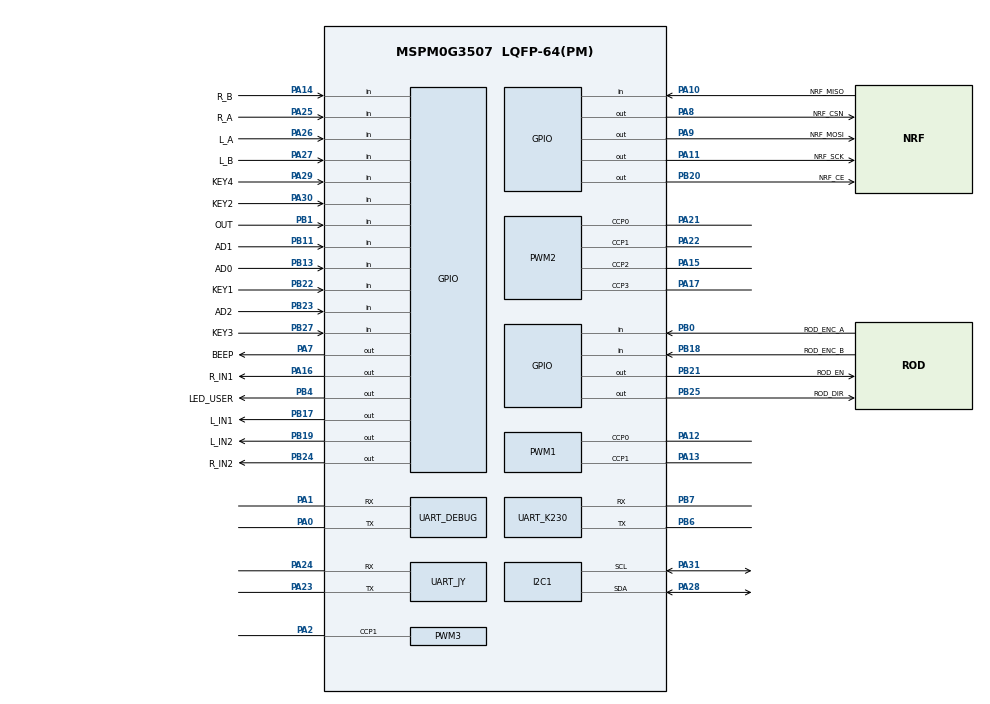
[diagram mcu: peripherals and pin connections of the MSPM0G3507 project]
/**
 * Revised local SysConfig script for the MSPM0G3507 E-car board.
 *
 * This file mirrors the checked-in ti_msp_dl_config.c/h logical names.
 * If SysConfig regenerates different macro names, keep App/Hardware code
 * mapped through Hardware/Board_Config.h.
 */
//@cliArgs --device "MSPM0G350X" --package "LQFP-64(PM)" --part "Default"
//@v2CliArgs --device "MSPM0G3507" --package "LQFP-64(PM)"
// @cliArgs --board /ti/boards/LP_MSPM0G3507 --rtos nortos

const GPIO   = scripting.addModule("/ti/driverlib/GPIO", {}, false);
const GPIO1  = GPIO.addInstance();
const GPIO2  = GPIO.addInstance();
const GPIO3  = GPIO.addInstance();
const GPIO4  = GPIO.addInstance();
const GPIO5  = GPIO.addInstance();
const GPIO_NRF = GPIO.addInstance();
const GPIO_RodStepper = GPIO.addInstance();
const GPIO_RodEncoder = GPIO.addInstance();
const I2C    = scripting.addModule("/ti/driverlib/I2C", {}, false);
const I2C1   = I2C.addInstance();
const PWM    = scripting.addModule("/ti/driverlib/PWM", {}, false);
const PWM1   = PWM.addInstance();
const PWM2   = PWM.addInstance();
const PWM3   = PWM.addInstance();
const TIMER  = scripting.addModule("/ti/driverlib/TIMER", {}, false);
const TIMER1 = TIMER.addInstance();
const UART   = scripting.addModule("/ti/driverlib/UART", {}, false);
const UART_DEBUG = UART.addInstance();
const SYSCTL = scripting.addModule("/ti/driverlib/SYSCTL");

const Board = scripting.addModule("/ti/driverlib/Board", {}, false);

/*
 * TB6612:
 * PWMA = TIMG0-C0, PWMB = TIMG0-C1.
 * STBY is tied to 5V and is intentionally not configured as an MCU GPIO.
 */
GPIO1.$name = "GPIO_MOTOR";
GPIO1.associatedPins.create(4);
GPIO1.associatedPins[0].$name        = "L_IN1";
GPIO1.associatedPins[0].assignedPort = "PORTB";
GPIO1.associatedPins[0].assignedPin  = "17";
GPIO1.associatedPins[0].pin.$assign  = "PB17";
GPIO1.associatedPins[0].initialValue = "CLEARED";
GPIO1.associatedPins[1].$name        = "L_IN2";
GPIO1.associatedPins[1].assignedPort = "PORTB";
GPIO1.associatedPins[1].assignedPin  = "19";
GPIO1.associatedPins[1].pin.$assign  = "PB19";
GPIO1.associatedPins[1].initialValue = "CLEARED";
GPIO1.associatedPins[2].$name        = "R_IN1";
GPIO1.associatedPins[2].assignedPort = "PORTA";
GPIO1.associatedPins[2].assignedPin  = "16";
GPIO1.associatedPins[2].pin.$assign  = "PA16";
GPIO1.associatedPins[2].initialValue = "CLEARED";
GPIO1.associatedPins[3].$name        = "R_IN2";
GPIO1.associatedPins[3].assignedPort = "PORTB";
GPIO1.associatedPins[3].assignedPin  = "24";
GPIO1.associatedPins[3].pin.$assign  = "PB24";
GPIO1.associatedPins[3].initialValue = "CLEARED";

/*
 * Encoder first pass:
 * M1 = left, M2 = right.  A phase is rising-edge interrupt input,
 * B phase is sampled for direction.
 * ENC_L_A/ENC_L_B = PA26/PA27, ENC_R_A/ENC_R_B = PA25/PA14.
 * PA25/PA26/PA27/PA14 do not accept SysConfig forced hysteresis on this
 * package, so keep internal pull-ups and enable the GPIO digital filter.
 */
GPIO2.$name = "GPIO_ENCODER";
GPIO2.associatedPins.create(4);
GPIO2.associatedPins[0].$name            = "L_A";
GPIO2.associatedPins[0].assignedPort     = "PORTA";
GPIO2.associatedPins[0].assignedPin      = "26";
GPIO2.associatedPins[0].pin.$assign      = "PA26";
GPIO2.associatedPins[0].direction        = "INPUT";
GPIO2.associatedPins[0].internalResistor = "PULL_UP";
GPIO2.associatedPins[0].inputFilter      = "8_CYCLES";
GPIO2.associatedPins[0].interruptEn      = true;
GPIO2.associatedPins[0].polarity         = "RISE_FALL";
GPIO2.associatedPins[1].$name            = "L_B";
GPIO2.associatedPins[1].assignedPort     = "PORTA";
GPIO2.associatedPins[1].assignedPin      = "27";
GPIO2.associatedPins[1].pin.$assign      = "PA27";
GPIO2.associatedPins[1].direction        = "INPUT";
GPIO2.associatedPins[1].internalResistor = "PULL_UP";
GPIO2.associatedPins[1].inputFilter      = "8_CYCLES";
GPIO2.associatedPins[2].$name            = "R_A";
GPIO2.associatedPins[2].assignedPort     = "PORTA";
GPIO2.associatedPins[2].assignedPin      = "25";
GPIO2.associatedPins[2].pin.$assign      = "PA25";
GPIO2.associatedPins[2].direction        = "INPUT";
GPIO2.associatedPins[2].internalResistor = "PULL_UP";
GPIO2.associatedPins[2].inputFilter      = "8_CYCLES";
GPIO2.associatedPins[2].interruptEn      = true;
GPIO2.associatedPins[2].polarity         = "RISE_FALL";
GPIO2.associatedPins[3].$name            = "R_B";
GPIO2.associatedPins[3].assignedPort     = "PORTA";
GPIO2.associatedPins[3].assignedPin      = "14";
GPIO2.associatedPins[3].pin.$assign      = "PA14";
GPIO2.associatedPins[3].direction        = "INPUT";
GPIO2.associatedPins[3].internalResistor = "PULL_UP";
GPIO2.associatedPins[3].inputFilter      = "8_CYCLES";

/*
 * Active board-test setup: a 4-channel infrared module reuses the former
 * 8-channel grayscale header.  PB23/PB11/PB13/PB01 are X1/X2/X3/X4 inputs.
 * All four external signals must be <= 3.3V.  Restore AD2/AD1/AD0 outputs
 * before reconnecting the CD4051-based 8-channel grayscale module.
 */
GPIO3.$name = "GPIO_GRAYSCALE";
GPIO3.associatedPins.create(4);
GPIO3.associatedPins[0].$name        = "AD2";
GPIO3.associatedPins[0].assignedPort = "PORTB";
GPIO3.associatedPins[0].assignedPin  = "23";
GPIO3.associatedPins[0].pin.$assign  = "PB23";
GPIO3.associatedPins[0].direction    = "INPUT";
GPIO3.associatedPins[0].internalResistor = "NONE";
GPIO3.associatedPins[0].inputFilter  = "8_CYCLES";
GPIO3.associatedPins[1].$name        = "AD1";
GPIO3.associatedPins[1].assignedPort = "PORTB";
GPIO3.associatedPins[1].assignedPin  = "11";
GPIO3.associatedPins[1].pin.$assign  = "PB11";
GPIO3.associatedPins[1].direction    = "INPUT";
GPIO3.associatedPins[1].internalResistor = "NONE";
GPIO3.associatedPins[1].inputFilter  = "8_CYCLES";
GPIO3.associatedPins[2].$name        = "AD0";
GPIO3.associatedPins[2].assignedPort = "PORTB";
GPIO3.associatedPins[2].assignedPin  = "13";
GPIO3.associatedPins[2].pin.$assign  = "PB13";
GPIO3.associatedPins[2].direction    = "INPUT";
GPIO3.associatedPins[2].internalResistor = "NONE";
GPIO3.associatedPins[2].inputFilter  = "8_CYCLES";
GPIO3.associatedPins[3].$name            = "OUT";
GPIO3.associatedPins[3].assignedPort     = "PORTB";
GPIO3.associatedPins[3].assignedPin      = "1";
GPIO3.associatedPins[3].pin.$assign      = "PB1";
GPIO3.associatedPins[3].direction        = "INPUT";
GPIO3.associatedPins[3].internalResistor = "NONE";
GPIO3.associatedPins[3].inputFilter      = "8_CYCLES";

GPIO4.$name = "GPIO_KEYS";
GPIO4.associatedPins.create(4);
GPIO4.associatedPins[0].$name            = "KEY1";
GPIO4.associatedPins[0].assignedPort     = "PORTB";
GPIO4.associatedPins[0].assignedPin      = "22";
GPIO4.associatedPins[0].pin.$assign      = "PB22";
GPIO4.associatedPins[0].direction        = "INPUT";
GPIO4.associatedPins[0].internalResistor = "PULL_UP";
GPIO4.associatedPins[1].$name            = "KEY2";
GPIO4.associatedPins[1].assignedPort     = "PORTA";
GPIO4.associatedPins[1].assignedPin      = "30";
GPIO4.associatedPins[1].pin.$assign      = "PA30";
GPIO4.associatedPins[1].direction        = "INPUT";
GPIO4.associatedPins[1].internalResistor = "PULL_UP";
GPIO4.associatedPins[2].$name            = "KEY3";
GPIO4.associatedPins[2].assignedPort     = "PORTB";
GPIO4.associatedPins[2].assignedPin      = "27";
GPIO4.associatedPins[2].pin.$assign      = "PB27";
GPIO4.associatedPins[2].direction        = "INPUT";
GPIO4.associatedPins[2].internalResistor = "PULL_UP";
GPIO4.associatedPins[3].$name            = "KEY4";
GPIO4.associatedPins[3].assignedPort     = "PORTA";
GPIO4.associatedPins[3].assignedPin      = "29";
GPIO4.associatedPins[3].pin.$assign      = "PA29";
GPIO4.associatedPins[3].direction        = "INPUT";
GPIO4.associatedPins[3].internalResistor = "PULL_UP";

GPIO5.$name = "GPIO_BOARD_IO";
GPIO5.associatedPins.create(2);
GPIO5.associatedPins[0].$name        = "LED_USER";
GPIO5.associatedPins[0].assignedPort = "PORTB";
GPIO5.associatedPins[0].assignedPin  = "4";
GPIO5.associatedPins[0].pin.$assign  = "PB4";
GPIO5.associatedPins[0].initialValue = "CLEARED";
GPIO5.associatedPins[1].$name        = "BEEP";
GPIO5.associatedPins[1].assignedPort = "PORTA";
GPIO5.associatedPins[1].assignedPin  = "7";
GPIO5.associatedPins[1].pin.$assign  = "PA7";
GPIO5.associatedPins[1].initialValue = "CLEARED";

PWM1.$name                      = "PWM_MOTOR";
PWM1.timerCount                 = 1600;
PWM1.peripheral.$assign         = "TIMG0";
PWM1.peripheral.ccp0Pin.$assign = "PA12";
PWM1.peripheral.ccp1Pin.$assign = "PA13";
PWM1.PWM_CHANNEL_0.$name        = "MOTOR_C0";
PWM1.PWM_CHANNEL_0.dutyCycle    = 0;
PWM1.PWM_CHANNEL_1.$name        = "MOTOR_C1";
PWM1.PWM_CHANNEL_1.dutyCycle    = 0;

/*
 * Servo PWM: TIMA0-C0..C3, 50Hz.  Physical H7/H15/H8/H14 connector routing
 * must be confirmed on the actual board before enabling ECAR_TEST_SERVO_ENABLE.
 */
PWM2.$name                      = "PWM_SERVO";
PWM2.ccIndex                    = [0,1,2,3];
PWM2.clockPrescale              = 32;
PWM2.timerCount                 = 20000;
PWM2.peripheral.$assign         = "TIMA0";
PWM2.peripheral.ccp0Pin.$assign = "PA21";
PWM2.peripheral.ccp1Pin.$assign = "PA22";
PWM2.peripheral.ccp2Pin.$assign = "PA15";
PWM2.peripheral.ccp3Pin.$assign = "PA17";
PWM2.PWM_CHANNEL_0.$name        = "SERVO_C0";
PWM2.PWM_CHANNEL_0.dutyCycle    = 0;
PWM2.PWM_CHANNEL_1.$name        = "SERVO_C1";
PWM2.PWM_CHANNEL_1.dutyCycle    = 0;
PWM2.PWM_CHANNEL_2.$name        = "SERVO_C2";
PWM2.PWM_CHANNEL_2.dutyCycle    = 0;
PWM2.PWM_CHANNEL_3.$name        = "SERVO_C3";
PWM2.PWM_CHANNEL_3.dutyCycle    = 0;

/*
 * Rod ball stepper STEP output. TIMG7-C1 / PA02 is timer-driven only;
 * the timer starts stopped and the initial output state is low (0% duty).
 * A 1 MHz timer clock keeps the commanded 100..2000 Hz range in 16 bits.
 */
PWM3.$name                      = "PWM_ROD_STEP";
PWM3.ccIndex                    = [1];
PWM3.clockPrescale              = 32;
PWM3.timerCount                 = 2500;
PWM3.timerStartTimer            = false;
PWM3.interrupts                 = ["ZERO_EVENT"];
PWM3.peripheral.$assign         = "TIMG7";
PWM3.peripheral.ccp1Pin.$assign = "PA2";
PWM3.PWM_CHANNEL_1.$name        = "ROD_STEP_C1";
PWM3.PWM_CHANNEL_1.dutyCycle    = 50;

TIMER1.$name              = "TIMER_SYS";
TIMER1.profile            = "Basic_Periodic";
TIMER1.timerPeriod        = "1 ms";
TIMER1.peripheral.$assign = "TIMG6";

/*
 * Keep diagnostics isolated from the K230 vision protocol:
 *   UART0 PA0/PA1: USB-TTL / debug console, 9600 baud.
 *   UART1 PB6/PB7: K230 bidirectional protocol, 460800 baud.
 * The two logical names are consumed by DebugSerial.c and Serial.c.
 */
UART_DEBUG.$name                    = "UART_DEBUG";
UART_DEBUG.profile                  = "CONFIG_PROFILE_1";
UART_DEBUG.peripheral.$assign       = "UART0";
UART_DEBUG.targetBaudRate           = 9600;
UART_DEBUG.enableInternalLoopback   = false;
UART_DEBUG.enableFIFO               = false;
UART_DEBUG.enabledInterrupts        = ["RX"];
UART_DEBUG.peripheral.txPin.$assign = "PA0";
UART_DEBUG.peripheral.rxPin.$assign = "PA1";

const UART_K230 = UART.addInstance();
UART_K230.$name                    = "UART_K230";
UART_K230.profile                  = "CONFIG_PROFILE_1";
UART_K230.peripheral.$assign       = "UART1";
UART_K230.targetBaudRate           = 460800;
UART_K230.enableInternalLoopback   = false;
UART_K230.enableFIFO               = false;
UART_K230.enabledInterrupts        = ["RX"];
UART_K230.peripheral.txPin.$assign = "PB6";
UART_K230.peripheral.rxPin.$assign = "PB7";

const UART_JY = UART.addInstance();
UART_JY.$name                    = "UART_JY61P";
UART_JY.profile                  = "CONFIG_PROFILE_1";
UART_JY.peripheral.$assign       = "UART2";
UART_JY.targetBaudRate           = 9600;
UART_JY.enableInternalLoopback   = false;
UART_JY.enableFIFO               = false;
UART_JY.enabledInterrupts        = ["RX"];
UART_JY.peripheral.txPin.$assign = "PA23";
UART_JY.peripheral.rxPin.$assign = "PA24";

I2C1.$name                     = "I2C_SHARED";
I2C1.basicEnableController     = true;
I2C1.basicControllerBusSpeed   = 100000;
I2C1.advAnalogGlitchFilter     = "DISABLED";
I2C1.peripheral.$assign        = "I2C0";
I2C1.peripheral.sclPin.$assign = "PA31";
I2C1.peripheral.sdaPin.$assign = "PA28";

GPIO_NRF.$name = "GPIO_NRF";
GPIO_NRF.associatedPins.create(5);
GPIO_NRF.associatedPins[0].$name            = "NRF_CE";
GPIO_NRF.associatedPins[0].assignedPort     = "PORTB";
GPIO_NRF.associatedPins[0].assignedPin      = "20";
GPIO_NRF.associatedPins[0].pin.$assign      = "PB20";
GPIO_NRF.associatedPins[0].direction        = "OUTPUT";
GPIO_NRF.associatedPins[0].initialValue     = "CLEARED";
GPIO_NRF.associatedPins[1].$name            = "NRF_CSN";
GPIO_NRF.associatedPins[1].assignedPort     = "PORTA";
GPIO_NRF.associatedPins[1].assignedPin      = "8";
GPIO_NRF.associatedPins[1].pin.$assign      = "PA8";
GPIO_NRF.associatedPins[1].direction        = "OUTPUT";
GPIO_NRF.associatedPins[1].initialValue     = "SET";
GPIO_NRF.associatedPins[2].$name            = "NRF_SCK";
GPIO_NRF.associatedPins[2].assignedPort     = "PORTA";
GPIO_NRF.associatedPins[2].assignedPin      = "11";
GPIO_NRF.associatedPins[2].pin.$assign      = "PA11";
GPIO_NRF.associatedPins[2].direction        = "OUTPUT";
GPIO_NRF.associatedPins[2].initialValue     = "CLEARED";
GPIO_NRF.associatedPins[3].$name            = "NRF_MOSI";
GPIO_NRF.associatedPins[3].assignedPort     = "PORTA";
GPIO_NRF.associatedPins[3].assignedPin      = "9";
GPIO_NRF.associatedPins[3].pin.$assign      = "PA9";
GPIO_NRF.associatedPins[3].direction        = "OUTPUT";
GPIO_NRF.associatedPins[3].initialValue     = "CLEARED";
GPIO_NRF.associatedPins[4].$name            = "NRF_MISO";
GPIO_NRF.associatedPins[4].assignedPort     = "PORTA";
GPIO_NRF.associatedPins[4].assignedPin      = "10";
GPIO_NRF.associatedPins[4].pin.$assign      = "PA10";
GPIO_NRF.associatedPins[4].direction        = "INPUT";
GPIO_NRF.associatedPins[4].internalResistor = "NONE";

/* PB25 DIR and PB21 active-low EN. EN deliberately stays low after init. */
GPIO_RodStepper.$name = "GPIO_ROD_STEPPER";
GPIO_RodStepper.associatedPins.create(2);
GPIO_RodStepper.associatedPins[0].$name        = "ROD_DIR";
GPIO_RodStepper.associatedPins[0].assignedPort = "PORTB";
GPIO_RodStepper.associatedPins[0].assignedPin  = "25";
GPIO_RodStepper.associatedPins[0].pin.$assign  = "PB25";
GPIO_RodStepper.associatedPins[0].direction    = "OUTPUT";
GPIO_RodStepper.associatedPins[0].initialValue = "CLEARED";
GPIO_RodStepper.associatedPins[1].$name        = "ROD_EN";
GPIO_RodStepper.associatedPins[1].assignedPort = "PORTB";
GPIO_RodStepper.associatedPins[1].assignedPin  = "21";
GPIO_RodStepper.associatedPins[1].pin.$assign  = "PB21";
GPIO_RodStepper.associatedPins[1].direction    = "OUTPUT";
GPIO_RodStepper.associatedPins[1].initialValue = "CLEARED";

/* Single rod encoder, 4x decoded in RodEncoder.c from PB00/PB18 edges. */
GPIO_RodEncoder.$name = "GPIO_ROD_ENCODER";
GPIO_RodEncoder.associatedPins.create(2);
GPIO_RodEncoder.associatedPins[0].$name            = "ROD_ENC_A";
GPIO_RodEncoder.associatedPins[0].assignedPort     = "PORTB";
GPIO_RodEncoder.associatedPins[0].assignedPin      = "0";
GPIO_RodEncoder.associatedPins[0].pin.$assign      = "PB0";
GPIO_RodEncoder.associatedPins[0].direction        = "INPUT";
GPIO_RodEncoder.associatedPins[0].internalResistor = "PULL_UP";
GPIO_RodEncoder.associatedPins[0].polarity         = "RISE_FALL";
GPIO_RodEncoder.associatedPins[0].interruptEn      = true;
GPIO_RodEncoder.associatedPins[1].$name            = "ROD_ENC_B";
GPIO_RodEncoder.associatedPins[1].assignedPort     = "PORTB";
GPIO_RodEncoder.associatedPins[1].assignedPin      = "18";
GPIO_RodEncoder.associatedPins[1].pin.$assign      = "PB18";
GPIO_RodEncoder.associatedPins[1].direction        = "INPUT";
GPIO_RodEncoder.associatedPins[1].internalResistor = "PULL_UP";
GPIO_RodEncoder.associatedPins[1].polarity         = "RISE_FALL";
GPIO_RodEncoder.associatedPins[1].interruptEn      = true;

SYSCTL.forceDefaultClkConfig = true;
SYSCTL.clockTreeEn = true;
